# SN32F400 register map
Vendor: SONiX Technology Co., Ltd.; Series: SN32F400; File version: 1.1
CPU: CM0 r0p0, little endian, no MPU, no FPU, 2 interrupt priority bits
Registers are 32-bit, read-write, reset 0x0 unless marked. A register's access mark holds for its fields unless they carry their own. Offsets are from the block's base; [hi:lo] are bit positions.

## SN_PFPA — Peripheral Function Pin Assignment
Base 0x40042000
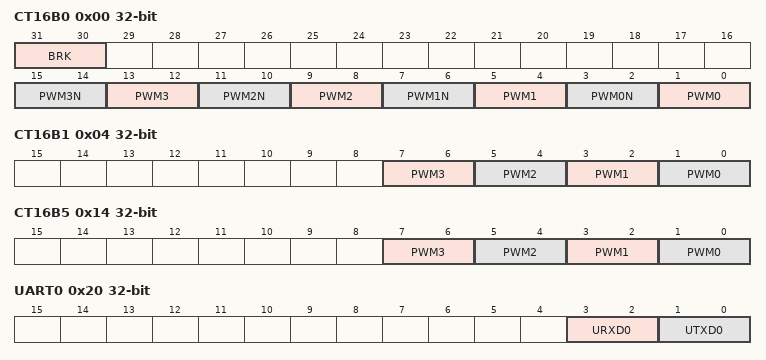
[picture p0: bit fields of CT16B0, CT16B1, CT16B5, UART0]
0x00 CT16B0 — Offset:0x00 PFPA for CT16B0 register
  [31:30] BRK — CT16B0_BRK assigned pin
    0=P0.5 (CT16B0_BRK=P0.5); 1=P0.10 (CT16B0_BRK=P0.10); 2=P1.12 (CT16B0_BRK=P1.12); 3=P2.10 (CT16B0_BRK=P2.10)
  [15:14] PWM3N — CT16B0_PWM3N assigned pin
    0=P0.0 (CT16B0_PWM3N=P0.0); 1=P0.1 (CT16B0_PWM3N=P0.1); 2=P0.2 (CT16B0_PWM3N=P0.2); 3=P3.1 (CT16B0_PWM3N=P3.1)
  [13:12] PWM3 — CT16B0_PWM3 assigned pin
    0=P0.1 (CT16B0_PWM3=P0.1); 1=P0.5 (CT16B0_PWM3=P0.5); 2=P0.3 (CT16B0_PWM3=P0.3); 3=P3.2 (CT16B0_PWM3=P3.2)
  [11:10] PWM2N — CT16B0_PWM2N assigned pin
    0=P2.8 (CT16B0_PWM2N=P2.8); 1=P2.6 (CT16B0_PWM2N=P2.6); 2=P2.9 (CT16B0_PWM2N=P2.9); 3=P0.1 (CT16B0_PWM2N=P0.1)
  [9:8] PWM2 — CT16B0_PWM2 assigned pin
    0=P2.7 (CT16B0_PWM2=P2.7); 1=P3.2 (CT16B0_PWM2=P3.2); 2=P0.0 (CT16B0_PWM2=P0.0); 3=P2.8 (CT16B0_PWM2=P2.8)
  [7:6] PWM1N — CT16B0_PWM1N assigned pin
    0=P0.2 (CT16B0_PWM1N=P0.2); 1=P0.0 (CT16B0_PWM1N=P0.0); 2=P2.8 (CT16B0_PWM1N=P2.8); 3=P2.4 (CT16B0_PWM1N=P2.4)
  [5:4] PWM1 — CT16B0_PWM1 assigned pin
    0=P2.9 (CT16B0_PWM1=P2.9); 1=P3.1 (CT16B0_PWM1=P3.1); 2=P0.1 (CT16B0_PWM1=P0.1); 3=P2.5 (CT16B0_PWM1=P2.5)
  [3:2] PWM0N — CT16B0_PWM0N assigned pin
    0=P0.3 (CT16B0_PWM0N=P0.3); 1=P0.1 (CT16B0_PWM0N=P0.1); 2=P2.7 (CT16B0_PWM0N=P2.7); 3=P1.1 (CT16B0_PWM0N=P1.1)
  [1:0] PWM0 — CT16B0_PWM0 assigned pin
    0=P0.2 (CT16B0_PWM0=P0.2); 1=P3.0 (CT16B0_PWM0=P3.0); 2=P2.6 (CT16B0_PWM0=P2.6); 3=P0.0 (CT16B0_PWM0=P0.0)
0x04 CT16B1 — Offset:0x04 PFPA for CT16B1 register
  [7:6] PWM3 — CT16B1_PWM3 assigned pin
    0=P0.7 (CT16B1_PWM3=P0.7); 1=P0.11 (CT16B1_PWM3=P0.11); 2=P2.1 (CT16B1_PWM3=P2.1); 3=P2.9 (CT16B1_PWM3=P2.9)
  [5:4] PWM2 — CT16B1_PWM2 assigned pin
    0=P0.6 (CT16B1_PWM2=P0.6); 1=P0.10 (CT16B1_PWM2=P0.10); 2=P2.0 (CT16B1_PWM2=P2.0); 3=P2.7 (CT16B1_PWM2=P2.7)
  [3:2] PWM1 — CT16B1_PWM1 assigned pin
    0=P0.5 (CT16B1_PWM1=P0.5); 1=P1.2 (CT16B1_PWM1=P1.2); 2=P2.8 (CT16B1_PWM1=P2.8); 3=P2.4 (CT16B1_PWM1=P2.4)
  [1:0] PWM0 — CT16B1_PWM0 assigned pin
    0=P2.10 (CT16B1_PWM0=P2.10); 1=P1.1 (CT16B1_PWM0=P1.1); 2=P1.12 (CT16B1_PWM0=P1.12); 3=P2.0 (CT16B1_PWM0=P2.0)
0x14 CT16B5 — Offset:0x14 PFPA for CT16B5 register
  [7:6] PWM3 — CT16B5_PWM3 assigned pin
    0=P2.9 (CT16B5_PWM3=P2.9); 1=P2.1 (CT16B5_PWM3=P2.1); 2=P1.3 (CT16B5_PWM3=P1.3); 3=P0.0 (CT16B5_PWM3=P0.0)
  [5:4] PWM2 — CT16B5_PWM2 assigned pin
    0=P2.8 (CT16B5_PWM2=P2.8); 1=P2.2 (CT16B5_PWM2=P2.2); 2=P1.0 (CT16B5_PWM2=P1.0); 3=P0.1 (CT16B5_PWM2=P0.1)
  [3:2] PWM1 — CT16B5_PWM1 assigned pin
    0=P2.7 (CT16B5_PWM1=P2.7); 1=P2.3 (CT16B5_PWM1=P2.3); 2=P1.2 (CT16B5_PWM1=P1.2); 3=P0.2 (CT16B5_PWM1=P0.2)
  [1:0] PWM0 — CT16B5_PWM0 assigned pin
    0=P2.6 (CT16B5_PWM0=P2.6); 1=P2.4 (CT16B5_PWM0=P2.4); 2=P1.1 (CT16B5_PWM0=P1.1); 3=P0.3 (CT16B5_PWM0=P0.3)
0x20 UART0 — Offset:0x20 PFPA for UART0 register
  [3:2] URXD0 — UART0_URXD0 assigned pin
    0=P0.11 (URXD0=P0.11); 1=P2.0 (URXD0=P2.0); 2=P3.2 (URXD0=P3.2); 3=P2.10 (URXD0=P2.10)
  [1:0] UTXD0 — UART0_UTXD0 assigned pin
    0=P0.10 (UTXD0=P0.10); 1=P2.1 (UTXD0=P2.1); 2=P3.1 (UTXD0=P3.1); 3=P2.9 (UTXD0=P2.9)
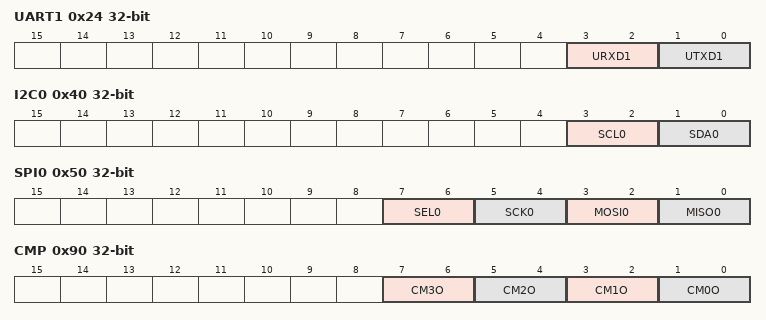
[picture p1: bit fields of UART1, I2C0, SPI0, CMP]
0x24 UART1 — Offset:0x24 PFPA for UART1 register
  [3:2] URXD1 — UART1_URXD1 assigned pin
    0=P1.8 (URXD1=P1.8); 1=P2.3 (URXD1=P2.3); 2=P2.8 (URXD1=P2.8); 3=P1.1 (URXD1=P1.1)
  [1:0] UTXD1 — UART1_UTXD1 assigned pin
    0=P1.9 (UTXD1=P1.9); 1=P2.2 (UTXD1=P2.2); 2=P2.7 (UTXD1=P2.7); 3=P1.0 (UTXD1=P1.0)
0x40 I2C0 — Offset:0x40 PFPA for I2C0 register
  [3:2] SCL0 — I2C_SCL0 assigned pin
    0=P0.6 (SCL0=P0.6); 1=P1.4 (SCL0=P1.4); 2=P0.10 (SCL0=P0.10); 3=P1.1 (SCL0=P1.1)
  [1:0] SDA0 — I2C_SDA0 assigned pin
    0=P0.7 (SDA0=P0.7); 1=P1.5 (SDA0=P1.5); 2=P0.11 (SDA0=P0.11); 3=P1.2 (SDA0=P1.2)
0x50 SPI0 — Offset:0x50 PFPA for SPI0 register
  [7:6] SEL0 — SPI_SEL0 assigned pin
    0=P0.1 (SEL0=P0.1); 1=P2.4 (SEL0=P2.4); 2=P1.8 (SEL0=P1.8); 3=P1.7 (SEL0=P1.7)
  [5:4] SCK0 — SPI_SCK0 assigned pin
    0=P0.0 (SCK0=P0.0); 1=P2.5 (SCK0=P2.5); 2=P1.0 (SCK0=P1.0); 3=P3.0 (SCK0=P3.0)
  [3:2] MOSI0 — SPI_MOSI0 assigned pin
    0=P0.3 (MOSI0=P0.3); 1=P2.7 (MOSI0=P2.7); 2=P1.2 (MOSI0=P1.2); 3=P3.2 (MOSI0=P3.2)
  [1:0] MISO0 — SPI_MISO0 assigned pin
    0=P0.2 (MISO0=P0.2); 1=P2.6 (MISO0=P2.6); 2=P1.1 (MISO0=P1.1); 3=P3.1 (MISO0=P3.1)
0x90 CMP — Offset:0x90 PFPA for CMP register
  [7:6] CM3O — CMP_CM3O assigned pin
    0=P3.0 (CM3O=P3.0); 1=P2.8 (CM3O=P2.8); 2=P3.12 (CM3O=P3.12); 3=P1.3 (CM3O=P1.3)
  [5:4] CM2O — CMP_CM2O assigned pin
    0=P1.0 (CM2O=P1.0); 1=P0.3 (CM2O=P0.3); 2=P3.8 (CM2O=P3.8); 3=P1.11 (CM2O=P1.11)
  [3:2] CM1O — CMP_CM1O assigned pin
    0=P2.2 (CM1O=P2.2); 1=P2.7 (CM1O=P2.7); 2=P1.10 (CM1O=P1.10); 3=P3.1 (CM1O=P3.1)
  [1:0] CM0O — CMP_CM0O assigned pin
    0=P2.0 (CM0O=P2.0); 1=P2.6 (CM0O=P2.6); 2=P1.6 (CM0O=P1.6); 3=P3.0 (CM0O=P3.0)
